# R7KA8T2AD register map
Vendor: Renesas Electronics Corporation; Series: RA8; File version: 1.10.02
CPU: CM85 r0p2, little endian, MPU, FPU, VTOR, 4 interrupt priority bits, 96 interrupts
Registers are 32-bit, read-write, reset 0x0 unless marked. A register's access mark holds for its fields unless they carry their own. Offsets are from the block's base; [hi:lo] are bit positions; {n}, {i} and the like mark numbered series; 'fields as' and 'values as' point back to an identical list.

## ESC_INI — Initial Configuration 1 for EtherCAT Slave Controller
Base 0x403A4000
Same registers: ESC_INI_NS 0x503A4000
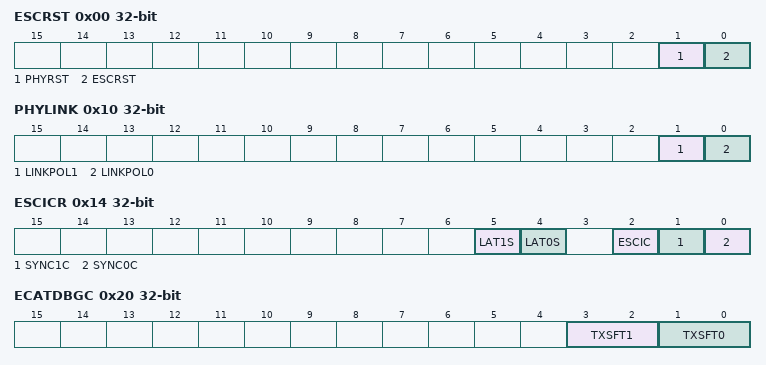
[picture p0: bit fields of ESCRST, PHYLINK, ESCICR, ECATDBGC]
0x00 ESCRST — ESC Reset Control Register
  [1] PHYRST — PHY Reset
    0=Reset; 1=Reset is released
  [0] ESCRST — ESC Reset
    0=Reset; 1=Reset is released
0x10 PHYLINK — PHY LINK Polarity Setting Register
  [1] LINKPOL1 — CAT1_LINKSTA Pin Polarity
    0=Active high; 1=Active Low
  [0] LINKPOL0 — CAT0_LINKSTA Pin Polarity
    0=Active high; 1=Active Low
0x14 ESCICR — ESC Interrupt Control Register
  [5] LAT1S — Select DC Latch Trigger 1 for ESC
    0=Select LATCH1 input from external; 1=Select LATCH1 input from ELC
  [4] LAT0S — Select DC Latch Trigger 0 for ESC
    0=Select LATCH0 input from external; 1=Select LATCH0 input from ELC
  [2] ESCIC
    0=An interrupt is generated when the PDI_IRQ is 1; 1=An interrupt is generated when the PDI_IRQ is 0
  [1] SYNC1C
    0=An interrupt is generated at the rising edge of the SYNC1 signal; 1=An interrupt is generated at the falling edge of the SYNC1 signal
  [0] SYNC0C
    0=An interrupt is generated at the rising edge of the SYNC0 signal; 1=An interrupt is generated at the falling edge of the SYNC0 signal
0x18 ECATOFFADR — EtherCAT PHY Offset Address Register
  [4:0] OADD
0x1C ECATOPMOD — EtherCAT Operation Mode Register
  [0] EEPROMSIZE
    0=16 Kbits or less; 1=32 Kbits to 4 Mbits
0x20 ECATDBGC — EtherCAT Debug Control Register
  [3:2] TXSFT1 — Port 1 TX Signal Delay Setting
    0=0 ns; 1=10 ns; 2=20 ns; 3=30 ns
  [1:0] TXSFT0 — Port 0 TX Signal Delay Setting
    0=0 ns; 1=10 ns; 2=20 ns; 3=30 ns

## PORT0 — Pmn Pin FunctionPort 0 Control RegistersPmn Pin Function Control Register
Base 0x40400000
Same registers: PORT5 0x404000A0, PORT6 0x404000C0, PORT7 0x404000E0, PORT8 0x40400100, PORT9 0x40400120, PORTA 0x40400140, PORTB 0x40400160, PORTC 0x40400180, PORTD 0x404001A0, PORT0_NS 0x50400000, PORT5_NS 0x504000A0, PORT6_NS 0x504000C0, PORT7_NS 0x504000E0, PORT8_NS 0x50400100, PORT9_NS 0x50400120, PORTA_NS 0x50400140, PORTB_NS 0x50400160, PORTC_NS 0x50400180, PORTD_NS 0x504001A0
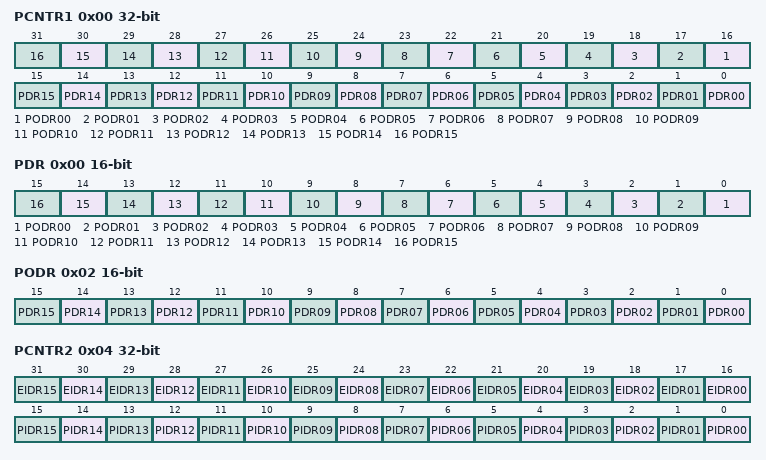
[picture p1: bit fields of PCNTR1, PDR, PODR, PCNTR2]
0x00 PCNTR1 — Port Control Register 1
  [n+16] PODR{n:02} (n=0..15) — Pmn Output Data
    0=Low output; 1=High output
  [n] PDR{n:02} (n=0..15) — Pmn Direction
    0=Input (functions as an input pin); 1=Output (functions as an output pin)
0x00 PDR 16-bit (alternate view of PCNTR1) — Port Control Register 1
  [all] fields
    0=Low output; 1=High output
  [n] PODR{n:02} (n=0..15) — Pmn Output Data
0x02 PODR 16-bit (alternate view of PCNTR1) — Port Control Register 1
  [all] fields
    values as PCNTR1.PDR00
  [n] PDR{n:02} (n=0..15) — Pmn Direction
0x04 PCNTR2 ro (reset mask 0xFFFF0000) — Port Control Register 2
  [n+16] EIDR{n:02} (n=0..15) — Port Event Input Data
    0=Low input; 1=High input
  [n] PIDR{n:02} (n=0..15) — Pmn State
    0=Low level; 1=High level
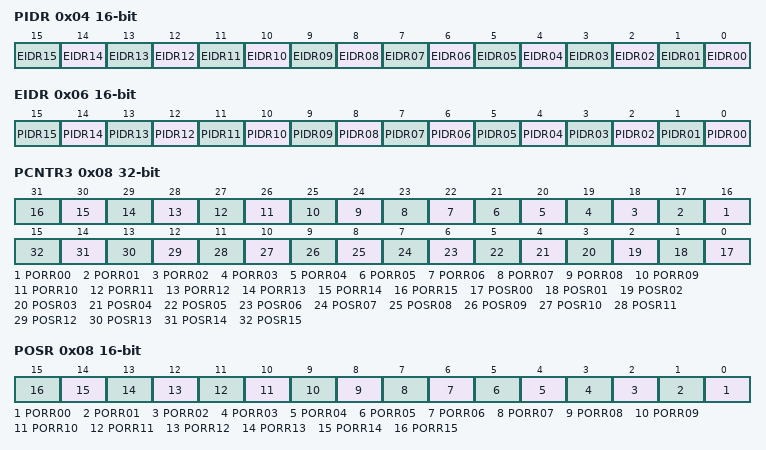
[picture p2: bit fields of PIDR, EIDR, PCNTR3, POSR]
0x04 PIDR 16-bit ro (alternate view of PCNTR2) — Port Control Register 2
  [all] fields
    0=Low input; 1=High input
  [n] EIDR{n:02} (n=0..15) — Port Event Input Data
0x06 EIDR 16-bit ro reset not defined (alternate view of PCNTR2) — Port Control Register 2
  [all] fields
    0=Low level; 1=High level
  [n] PIDR{n:02} (n=0..15) — Pmn State
0x08 PCNTR3 wo — Port Control Register 3
  [n+16] PORR{n:02} (n=0..15) — Pmn Output Reset
    0=No effect on output; 1=Low output
  [n] POSR{n:02} (n=0..15) — Pmn Output Set
    0=No effect on output; 1=High output
0x08 POSR 16-bit wo (alternate view of PCNTR3) — Port Control Register 3
  [all] fields
    0=No effect on output; 1=Low output
  [n] PORR{n:02} (n=0..15) — Pmn Output Reset
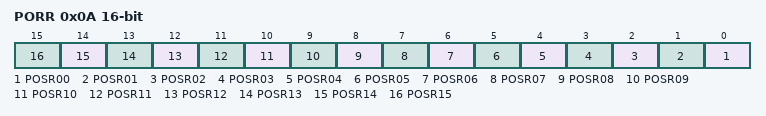
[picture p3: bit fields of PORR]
0x0A PORR 16-bit wo (alternate view of PCNTR3) — Port Control Register 3
  [all] fields
    0=No effect on output; 1=High output
  [n] POSR{n:02} (n=0..15) — Pmn Output Set

## PORT1 — Pmn Pin FunctionPort 1 Control RegistersPmn Pin Function Control Register
Base 0x40400020
Same registers: PORT2 0x40400040, PORT3 0x40400060, PORT4 0x40400080, PORT1_NS 0x50400020, PORT2_NS 0x50400040, PORT3_NS 0x50400060, PORT4_NS 0x50400080
Registers as PORT0; these are added or differ:
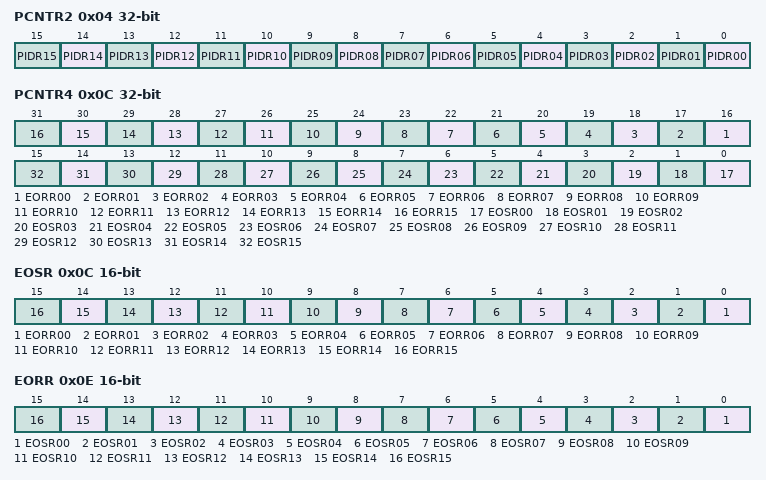
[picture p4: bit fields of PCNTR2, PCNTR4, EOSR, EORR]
0x04 PCNTR2 ro (reset mask 0xFFFF0000) — Port Control Register 2
  [all] fields
    0=Low level; 1=High level
  [n] PIDR{n:02} (n=0..15) — Pmn State
0x04 PIDR 16-bit ro (alternate view of PCNTR2) — Port Control Register 2
0x0C PCNTR4 — Port Control Register 4
  [n+16] EORR{n:02} (n=0..15) — Pmn Event Output Reset
    0=No effect on output; 1=Low output
  [n] EOSR{n:02} (n=0..15) — Pmn Event Output Set
    0=No effect on output; 1=High output
0x0C EOSR 16-bit (alternate view of PCNTR4) — Port Control Register 4
  [all] fields
    0=No effect on output; 1=Low output
  [n] EORR{n:02} (n=0..15) — Pmn Event Output Reset
0x0E EORR 16-bit (alternate view of PCNTR4) — Port Control Register 4
  [all] fields
    0=No effect on output; 1=High output
  [n] EOSR{n:02} (n=0..15) — Pmn Event Output Set
